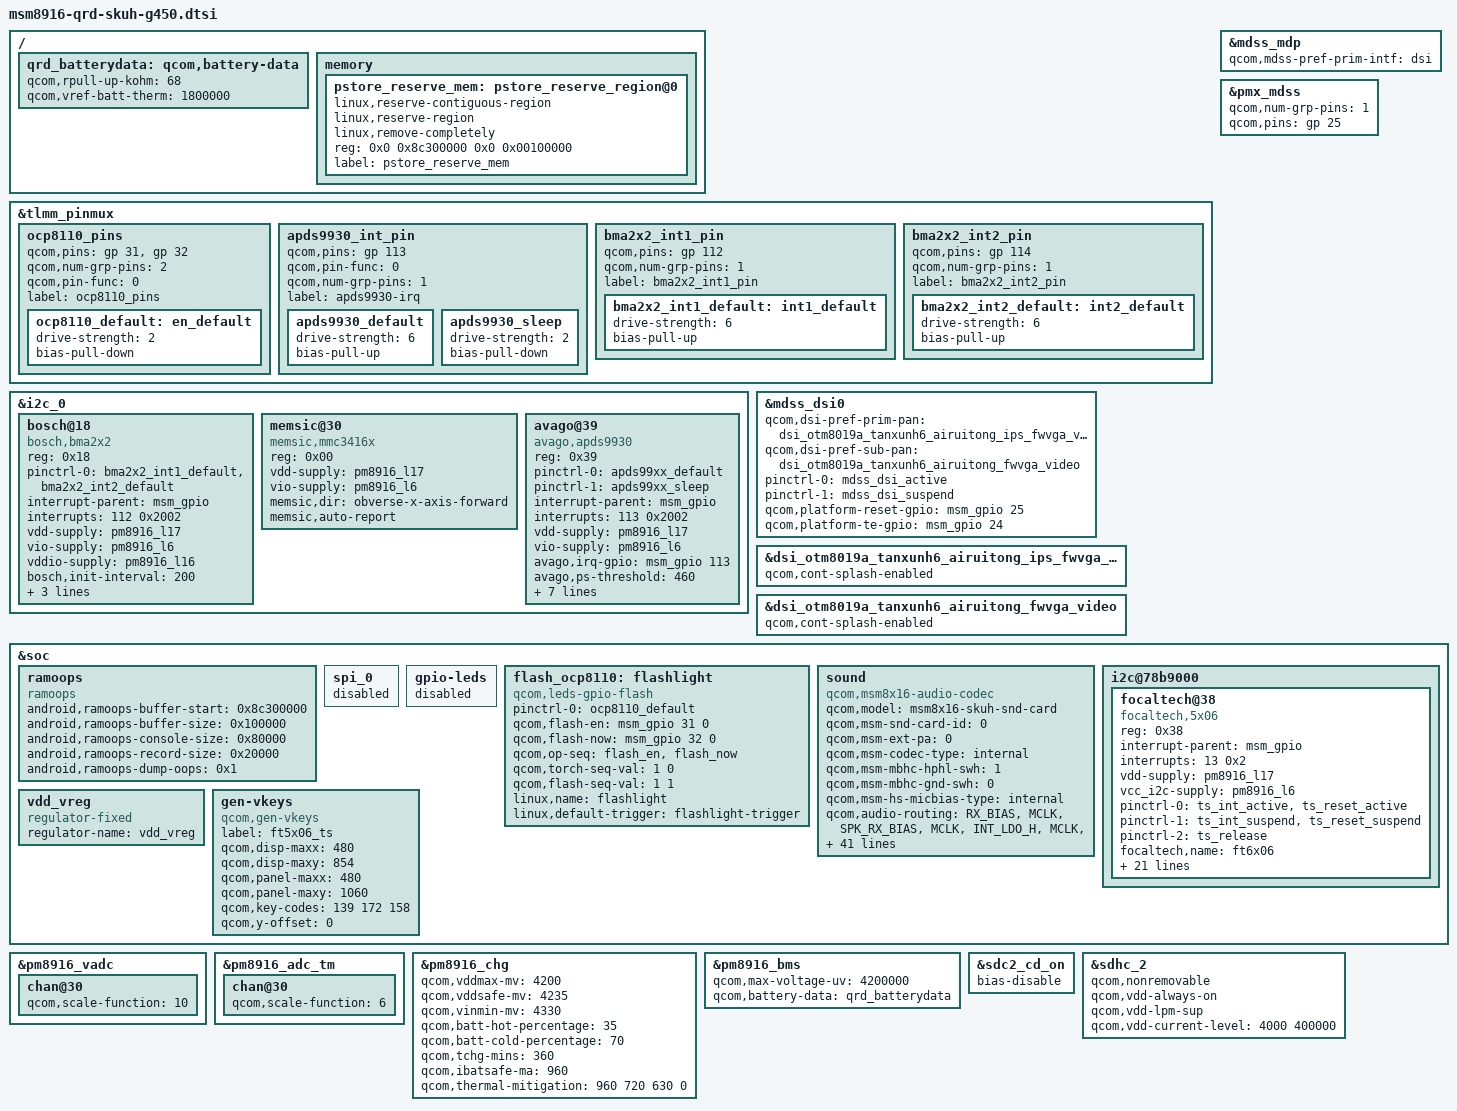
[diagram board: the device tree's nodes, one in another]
/* Copyright (c) 2014, The Linux Foundation. All rights reserved.
 *
 * This program is free software; you can redistribute it and/or modify
 * it under the terms of the GNU General Public License version 2 and
 * only version 2 as published by the Free Software Foundation.
 *
 * This program is distributed in the hope that it will be useful,
 * but WITHOUT ANY WARRANTY; without even the implied warranty of
 * MERCHANTABILITY or FITNESS FOR A PARTICULAR PURPOSE.  See the
 * GNU General Public License for more details.
 */

#include "msm8916-camera-sensor-g450.dtsi"
#include "dsi-panel-otm8019a-tanxunh6-airuitong-fwvga-video.dtsi"
#include "dsi-panel-otm8019a-tanxunh6-airuitong-ips-fwvga-video.dtsi"
#include "msm8916-pinctrl-g450.dtsi"

&tlmm_pinmux {
	ocp8110_pins {
		qcom,pins = <&gp 31>, <&gp 32>;
		qcom,num-grp-pins = <2>;
		qcom,pin-func = <0>;
		label = "ocp8110_pins";
		ocp8110_default: en_default {
			  drive-strength = <2>;
			  bias-pull-down;
		};
	};

	apds9930_int_pin {
		qcom,pins = <&gp 113>;
		qcom,pin-func = <0>;
		qcom,num-grp-pins = <1>;
		label = "apds9930-irq";
		apds9930_default: apds9930_default {
		drive-strength = <6>;
		bias-pull-up;
		};
		apds9930_sleep: apds9930_sleep {
			drive-strength = <2>;
			bias-pull-down;
		};
	};

	bma2x2_int1_pin {
		qcom,pins = <&gp 112>;
		qcom,num-grp-pins = <1>;
		label = "bma2x2_int1_pin";
		bma2x2_int1_default: int1_default {
			  drive-strength = <6>;
			  bias-pull-up;
		};
	};

	bma2x2_int2_pin {
		qcom,pins = <&gp 114>;
		qcom,num-grp-pins = <1>;
		label = "bma2x2_int2_pin";
		bma2x2_int2_default: int2_default {
			  drive-strength = <6>;
			  bias-pull-up;
		};
	};	

};

&i2c_0 { /* BLSP1 QUP2 */

	bosch@18 { /* Accelerometer sensor */
		compatible = "bosch,bma2x2";
		reg = <0x18>;
		pinctrl-names = "default";
		pinctrl-0 = <&bma2x2_int1_default &bma2x2_int2_default>;
		interrupt-parent = <&msm_gpio>;
		interrupts = <112 0x2002>;
		vdd-supply = <&pm8916_l17>;
		vio-supply = <&pm8916_l6>;
		vddio-supply = <&pm8916_l16>; 
		bosch,init-interval = <200>;
		bosch,place = <2>;
		bosch,gpio-int1 = <&msm_gpio 112 0x2002>;
		bosch,gpio-int2 = <&msm_gpio 114 0x2002>;
	};

	memsic@30 { 
		compatible = "memsic,mmc3416x";
		reg = <0x00>;
		vdd-supply = <&pm8916_l17>;
		vio-supply = <&pm8916_l6>;
		memsic,dir = "obverse-x-axis-forward";
		memsic,auto-report;
	};

	avago@39 {
		compatible = "avago,apds9930";
		reg = <0x39>;
		pinctrl-names = "default","sleep";
		pinctrl-0 = <&apds99xx_default>;
		pinctrl-1 = <&apds99xx_sleep>;
		interrupt-parent = <&msm_gpio>;
		interrupts = <113 0x2002>;
		vdd-supply = <&pm8916_l17>;
		vio-supply = <&pm8916_l6>;
		avago,irq-gpio = <&msm_gpio 113 0x2002>;
		avago,ps-threshold = <460>;
		avago,ps-hysteresis-threshold = <310>;
		avago,ps-pulse = <5>;//0x3A
		avago,ps-pgain = <0>;
		avago,als-B = <186>;
		avago,als-C = <75>;
		avago,als-D = <129>;
		avago,ga-value = <136>;//98
	};

};

&mdss_mdp {
	qcom,mdss-pref-prim-intf = "dsi";
};

&pmx_mdss {
	qcom,num-grp-pins = <1>;
	qcom,pins = <&gp 25>;
};

&mdss_dsi0 {
	qcom,dsi-pref-prim-pan = <&dsi_otm8019a_tanxunh6_airuitong_ips_fwvga_video>;
	qcom,dsi-pref-sub-pan = <&dsi_otm8019a_tanxunh6_airuitong_fwvga_video>;
	pinctrl-names = "mdss_default", "mdss_sleep";
	pinctrl-0 = <&mdss_dsi_active>;
	pinctrl-1 = <&mdss_dsi_suspend>;

	qcom,platform-reset-gpio = <&msm_gpio 25 0>;

    qcom,platform-te-gpio = <&msm_gpio 24 0>;

};

&dsi_otm8019a_tanxunh6_airuitong_ips_fwvga_video {
	qcom,cont-splash-enabled;
};

&dsi_otm8019a_tanxunh6_airuitong_fwvga_video {
	qcom,cont-splash-enabled;
};

&soc {

	ramoops {
		compatible = "ramoops";
		status = "ok";

		android,ramoops-buffer-start = <0x8c300000>;
		android,ramoops-buffer-size = <0x100000>;
		android,ramoops-console-size = <0x80000>;
		android,ramoops-record-size = <0x20000>;
		android,ramoops-dump-oops = <0x1>;
	};

	spi_0 {
		status = "disabled";
	};

	gpio-leds {
		status = "disabled";
	};

	flash_ocp8110:flashlight {
		compatible = "qcom,leds-gpio-flash";
		status = "okay";
		pinctrl-names = "flash_default";
		pinctrl-0 = <&ocp8110_default>;
		qcom,flash-en = <&msm_gpio 31 0>;
		qcom,flash-now = <&msm_gpio 32 0>;
		qcom,op-seq = "flash_en", "flash_now";
		qcom,torch-seq-val = <1 0>;
		qcom,flash-seq-val = <1 1>;		
		linux,name = "flashlight";
		linux,default-trigger = "flashlight-trigger";
	};

	sound {
			compatible = "qcom,msm8x16-audio-codec";
			qcom,model = "msm8x16-skuh-snd-card";
			qcom,msm-snd-card-id = <0>;
            qcom,msm-ext-pa = <0>;//miaoxiaoming modify for internal PA
			qcom,msm-codec-type = "internal";
			qcom,msm-mbhc-hphl-swh = <1>;
			qcom,msm-mbhc-gnd-swh = <0>;
			/*miaoxiaoming add to fixed can not find the soundcard*/
			qcom,msm-hs-micbias-type = "internal";
			qcom,audio-routing =
				"RX_BIAS", "MCLK",
				"SPK_RX_BIAS", "MCLK",
				"INT_LDO_H", "MCLK",
				"MIC BIAS Internal1", "Handset Mic",
				"MIC BIAS Internal2", "Headset Mic",
				"MIC BIAS Internal1", "Secondary Mic",
				"AMIC1", "MIC BIAS Internal1",
				"AMIC2", "MIC BIAS Internal2",
				"AMIC3", "MIC BIAS Internal1";			
			/*miaoxiaoming add end*/			
			pinctrl-names = "cdc_lines_act",
					"cdc_lines_sus";
			pinctrl-0 = <&cdc_pdm_lines_act>;
			pinctrl-1 = <&cdc_pdm_lines_sus>;
			asoc-platform = <&pcm0>, <&pcm1>, <&voip>, <&voice>,
					<&loopback>, <&compress>, <&hostless>,
					<&afe>, <&lsm>, <&routing>, <&lpa>;
			asoc-platform-names = "msm-pcm-dsp.0", "msm-pcm-dsp.1",
					"msm-voip-dsp", "msm-pcm-voice", "msm-pcm-loopback",
					"msm-compress-dsp", "msm-pcm-hostless", "msm-pcm-afe",
					"msm-lsm-client", "msm-pcm-routing", "msm-pcm-lpa";
			asoc-cpu = <&dai_pri_auxpcm>, <&dai_hdmi>,
					<&dai_mi2s0>, <&dai_mi2s1>, <&dai_mi2s2>, <&dai_mi2s3>,
					<&sb_0_rx>, <&sb_0_tx>, <&sb_1_rx>, <&sb_1_tx>,
					<&sb_3_rx>, <&sb_3_tx>, <&sb_4_rx>, <&sb_4_tx>,
					<&bt_sco_rx>, <&bt_sco_tx>, <&int_fm_rx>, <&int_fm_tx>,
					<&afe_pcm_rx>, <&afe_pcm_tx>, <&afe_proxy_rx>,
					<&afe_proxy_tx>, <&incall_record_rx>,
					<&incall_record_tx>, <&incall_music_rx>,
					<&incall_music_2_rx>;
			asoc-cpu-names = "msm-dai-q6-auxpcm.1", "msm-dai-q6-hdmi.8",
					"msm-dai-q6-mi2s.0", "msm-dai-q6-mi2s.1",
					"msm-dai-q6-mi2s.2", "msm-dai-q6-mi2s.3",
					"msm-dai-q6-dev.16384", "msm-dai-q6-dev.16385",
					"msm-dai-q6-dev.16386", "msm-dai-q6-dev.16387",
					"msm-dai-q6-dev.16390", "msm-dai-q6-dev.16391",
					"msm-dai-q6-dev.16392", "msm-dai-q6-dev.16393",
					"msm-dai-q6-dev.12288", "msm-dai-q6-dev.12289",
					"msm-dai-q6-dev.12292", "msm-dai-q6-dev.12293",
					"msm-dai-q6-dev.224", "msm-dai-q6-dev.225",
					"msm-dai-q6-dev.241", "msm-dai-q6-dev.240",
					"msm-dai-q6-dev.32771", "msm-dai-q6-dev.32772",
					"msm-dai-q6-dev.32773", "msm-dai-q6-dev.32770";
			asoc-codec = <&stub_codec>, <&pm8916_tombak_dig>;
			asoc-codec-names = "msm-stub-codec.1", "tombak_codec";
	};

	i2c@78b9000 { /* BLSP1 QUP5 */

		/*miaoxiaoming add here to share with all the msm8916 project*/
		focaltech@38 {
			compatible = "focaltech,5x06";
			reg = <0x38>;
			interrupt-parent = <&msm_gpio>;
			interrupts = <13 0x2>;
			vdd-supply = <&pm8916_l17>;
			vcc_i2c-supply = <&pm8916_l6>;
			/* pins used by touchscreen */
			pinctrl-names = "pmx_ts_active","pmx_ts_suspend","pmx_ts_release";
			pinctrl-0 = <&ts_int_active &ts_reset_active>;
			pinctrl-1 = <&ts_int_suspend &ts_reset_suspend>;
			pinctrl-2 = <&ts_release>;
			focaltech,name = "ft6x06";
			focaltech,family-id = <0x55>;
			focaltech,reset-gpio = <&msm_gpio 12 0x00>;
			focaltech,irq-gpio = <&msm_gpio 13 0x00>;
			focaltech,enable-gpio = <&msm_gpio 10 0x00>;
			focaltech,display-coords = <0 0 480 854>;
			focaltech,panel-coords = <0 0 480 960>;
			focaltech,button-map= <100 202 370>;
			focaltech,no-force-update;
			focaltech,i2c-pull-up;
			focaltech,group-id = <1>;
			focaltech,hard-reset-delay-ms = <20>;
			focaltech,soft-reset-delay-ms = <150>;
			focaltech,num-max-touches = <5>;
			focaltech,fw-name = "ft_8226_qrd_1080p_fw.bin";
			focaltech,fw-delay-aa-ms = <50>;
			focaltech,fw-delay-55-ms = <30>;
			focaltech,fw-upgrade-id1 = <0x79>;
			focaltech,fw-upgrade-id2 = <0x08>;
			focaltech,fw-delay-readid-ms = <10>;
			focaltech,fw-delay-era-flsh-ms = <2000>;
			focaltech,ignore-id-check;
		};
		
	};

	vdd_vreg: vdd_vreg {
		compatible = "regulator-fixed";
		status = "ok";
		regulator-name = "vdd_vreg";
	};

	gen-vkeys {
		compatible = "qcom,gen-vkeys";
		label = "ft5x06_ts";
		qcom,disp-maxx = <480>;
		qcom,disp-maxy = <854>;
		qcom,panel-maxx = <480>;
		qcom,panel-maxy = <1060>;
		qcom,key-codes = <139 172 158>;
		qcom,y-offset = <0>;
	};

};

&pm8916_vadc {
	chan@30 {
		qcom,scale-function = <10>;
	};
};

&pm8916_adc_tm {
	chan@30 {
		qcom,scale-function = <6>;
	};
};

&pm8916_chg {
	qcom,vddmax-mv = <4200>;
	qcom,vddsafe-mv = <4235>;
	qcom,vinmin-mv = <4330>;
	qcom,batt-hot-percentage = <35>;
	qcom,batt-cold-percentage = <70>;
	qcom,tchg-mins = <360>;
	qcom,ibatsafe-ma = <960>;
	qcom,thermal-mitigation = <960 720 630 0>;
	status = "okay";
};

/ {
	qrd_batterydata: qcom,battery-data {
		qcom,rpull-up-kohm = <68>;
		qcom,vref-batt-therm = <1800000>;
		#include "batterydata-qrd-polytron-g450-4v35-1550mah.dtsi"
	};
};

&pm8916_bms{
       qcom,max-voltage-uv = <4200000>;
       qcom,battery-data = <&qrd_batterydata>;
	   status = "ok";
};

&sdc2_cd_on {
	/delete-property/ bias-pull-up;
	bias-disable;
};

&sdhc_2 {
	qcom,nonremovable;
	qcom,vdd-always-on;
	qcom,vdd-lpm-sup;

	qcom,vdd-current-level = <4000 400000>;
	/delete-property/ cd-gpios;
};

/ {
	memory {
		pstore_reserve_mem: pstore_reserve_region@0 {
			linux,reserve-contiguous-region;
			linux,reserve-region;
			linux,remove-completely;
			reg = <0x0 0x8c300000 0x0 0x00100000>;
			label = "pstore_reserve_mem";
		};
	};
};

